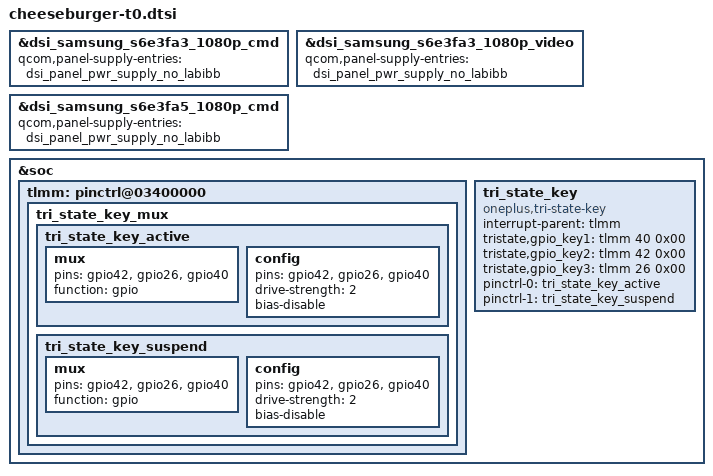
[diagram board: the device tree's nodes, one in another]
/* Copyright (c) 2015-2016, The Linux Foundation. All rights reserved.
 *
 * This program is free software; you can redistribute it and/or modify
 * it under the terms of the GNU General Public License version 2 and
 * only version 2 as published by the Free Software Foundation.
 *
 * This program is distributed in the hope that it will be useful,
 * but WITHOUT ANY WARRANTY; without even the implied warranty of
 * MERCHANTABILITY or FITNESS FOR A PARTICULAR PURPOSE.  See the
 * GNU General Public License for more details.
 */

#include "dsi-panel-samsung_s6e3fa3_1080p_cmd.dtsi"
#include "dsi-panel-samsung_s6e3fa3_1080p_video.dtsi"
#include "dsi-panel-samsung_s6e3fa5_1080p_cmd.dtsi"

&dsi_samsung_s6e3fa3_1080p_cmd {
  qcom,panel-supply-entries = <&dsi_panel_pwr_supply_no_labibb>;
	#include "pxlw-iris-samsung_s6e3fa3.dtsi"
};

&dsi_samsung_s6e3fa3_1080p_video {
  qcom,panel-supply-entries = <&dsi_panel_pwr_supply_no_labibb>;
	#include "pxlw-iris-samsung_s6e3fa3.dtsi"
};

&dsi_samsung_s6e3fa5_1080p_cmd {
  qcom,panel-supply-entries = <&dsi_panel_pwr_supply_no_labibb>;
	#include "pxlw-iris-samsung_s6e3fa3.dtsi"
};
&soc {
        tlmm: pinctrl@03400000 {
                tri_state_key_mux {
                        tri_state_key_active: tri_state_key_active {
                                mux {
                                        pins = "gpio42","gpio26","gpio40";
                                        function = "gpio";
                                };

                                config {
                                        pins = "gpio42","gpio26","gpio40";
                                        drive-strength = <2>;
                                        bias-disable;
                                };
                        };

                        tri_state_key_suspend: tri_state_key_suspend {
                                mux {
                                        pins = "gpio42","gpio26","gpio40";
                                        function = "gpio";
                                };

                                config {
                                        pins = "gpio42","gpio26","gpio40";
                                        drive-strength = <2>;
                                        bias-disable;
                                };
                        };
                };
        };
        /* Tri-state key */
        tri_state_key {
                compatible = "oneplus,tri-state-key";
                status = "okay";
                interrupt-parent = <&tlmm>;
                tristate,gpio_key1 = <&tlmm 40 0x00>;
                tristate,gpio_key2 = <&tlmm 42 0x00>;
                tristate,gpio_key3 = <&tlmm 26 0x00>;

                pinctrl-names = "pmx_tri_state_key_active", "pmx_tri_state_key_suspend";
                pinctrl-0 = <&tri_state_key_active>;
                pinctrl-1 = <&tri_state_key_suspend>;
        };

};

